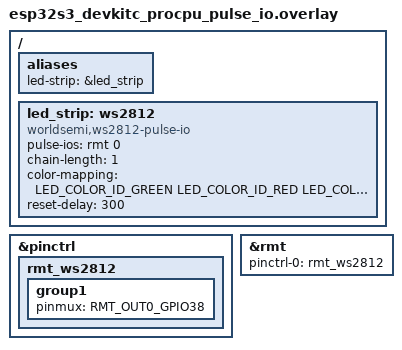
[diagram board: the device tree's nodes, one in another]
/*
 * Copyright (c) 2026 Espressif Systems (Shanghai) Co., Ltd.
 *
 * SPDX-License-Identifier: Apache-2.0
 */

#include <zephyr/dt-bindings/led/led.h>

/ {
	aliases {
		led-strip = &led_strip;
	};

	led_strip: ws2812 {
		compatible = "worldsemi,ws2812-pulse-io";
		pulse-ios = <&rmt 0>;
		chain-length = <1>;
		color-mapping = <LED_COLOR_ID_GREEN
				 LED_COLOR_ID_RED
				 LED_COLOR_ID_BLUE>;
		reset-delay = <300>;
	};
};

&pinctrl {
	rmt_ws2812: rmt_ws2812 {
		group1 {
			pinmux = <RMT_OUT0_GPIO38>;
		};
	};
};

&rmt {
	pinctrl-0 = <&rmt_ws2812>;
	pinctrl-names = "default";
	status = "okay";
};
